# nrf54lv10a_enga_application register map
Vendor: Nordic Semiconductor; Series: nrf54l; File version: 1
CPU: CM33 r0p4, little endian, MPU, FPU, 3 interrupt priority bits, 270 interrupts, 4 SAU regions
Registers are 32-bit, read-write, reset 0x0 unless marked. A register's access mark holds for its fields unless they carry their own. Offsets are from the block's base; [hi:lo] are bit positions; lines under a group give offsets from that group; {n}, {i} and the like mark numbered series; 'fields as' and 'values as' point back to an identical list.

## GLOBAL_KMU_S — Key management unit
Base 0x50049000
0x00 TASKS_PROVISION wo — Provision key slot
  [0] TASKS_PROVISION
    1=Trigger task
0x04 TASKS_PUSH wo — Push key slot
  [0] TASKS_PUSH
    1=Trigger task
0x08 TASKS_REVOKE wo — Revoke key slot
  [0] TASKS_REVOKE
    1=Trigger task
0x0C TASKS_READMETADATA wo — Read key slot metadata into METADATA register
  [0] TASKS_READMETADATA
    1=Trigger task
0x10 TASKS_PUSHBLOCK wo — Block only the PUSH operation of a key slot, preventing the key slot from being PUSHED until next reset. The task is kept for backwards compatibility.
  [0] TASKS_PUSHBLOCK
    1=Trigger task
0x14 TASKS_BLOCK wo — Block the PROVISION, PUSH, and REVOKE operations of a key slot, preventing the key slot from being PROVISIONED, PUSHED, or REVOKED until next reset
  [0] TASKS_BLOCK
    1=Trigger task
0x100 EVENTS_PROVISIONED — Key slot successfully provisioned
  [0] EVENTS_PROVISIONED
    0=NotGenerated (Event not generated); 1=Generated (Event generated)
0x104 EVENTS_PUSHED — Key slot successfully pushed
  [0] EVENTS_PUSHED
    values as EVENTS_PROVISIONED.EVENTS_PROVISIONED
0x108 EVENTS_REVOKED — Key slot has been revoked and can no longer be used
  [0] EVENTS_REVOKED
    values as EVENTS_PROVISIONED.EVENTS_PROVISIONED
0x10C EVENTS_ERROR — Error generated during PROVISION, PUSH, READMETADATA or REVOKE operations. Triggering the PROVISION, PUSH and REVOKE tasks on a BLOCKED keyslot will also generate this event.
  [0] EVENTS_ERROR
    values as EVENTS_PROVISIONED.EVENTS_PROVISIONED
0x110 EVENTS_METADATAREAD — Key slot metadata has been read into METADATA register
  [0] EVENTS_METADATAREAD
    values as EVENTS_PROVISIONED.EVENTS_PROVISIONED
0x114 EVENTS_PUSHBLOCKED — The PUSHBLOCK operation was successful. The event is kept for backwards compatibility.
  [0] EVENTS_PUSHBLOCKED
    values as EVENTS_PROVISIONED.EVENTS_PROVISIONED
0x118 EVENTS_BLOCKED — The BLOCK operation was successful
  [0] EVENTS_BLOCKED
    values as EVENTS_PROVISIONED.EVENTS_PROVISIONED
0x400 STATUS ro — KMU status register
  [0] STATUS — KMU status
    0=Ready (KMU is ready for new operation); 1=Busy (KMU is busy, an operation is in progress)
0x500 KEYSLOT — Select key slot to operate on
  [7:0] ID — Select key slot ID to provision, push, read METADATA, revoke or block when the corresponding task is triggered.
0x504 SRC — Source address for provisioning
  [31:0] SRC — Source address for TASKS_PROVISION.
0x508 METADATA — Key slot metadata as read by TASKS_READMETADATA.
  [31:0] METADATA — Read metadata.

## GLOBAL_ECB00_NS — AES ECB Mode Encryption 0
Base 0x4004B000
Same registers: GLOBAL_ECB00_S 0x5004B000
0x00 TASKS_START wo — Start ECB block encrypt
  [0] TASKS_START
    1=Trigger task
0x04 TASKS_STOP wo — Abort a possible executing ECB operation
  [0] TASKS_STOP
    1=Trigger task
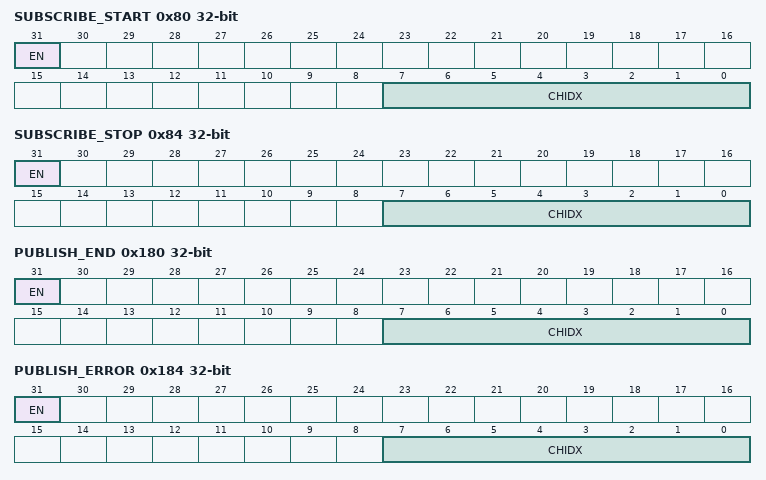
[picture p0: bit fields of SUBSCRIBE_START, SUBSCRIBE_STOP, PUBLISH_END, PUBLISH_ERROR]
0x80 SUBSCRIBE_START — Subscribe configuration for task START
  [31] EN
    0=Disabled (Disable subscription); 1=Enabled (Enable subscription)
  [7:0] CHIDX — DPPI channel that task START will subscribe to
0x84 SUBSCRIBE_STOP — Subscribe configuration for task STOP
  [31] EN
    values as SUBSCRIBE_START.EN
  [7:0] CHIDX — DPPI channel that task STOP will subscribe to
0x100 EVENTS_END — ECB block encrypt complete
  [0] EVENTS_END
    0=NotGenerated (Event not generated); 1=Generated (Event generated)
0x104 EVENTS_ERROR — ECB block encrypt aborted because of a STOP task or due to an error
  [0] EVENTS_ERROR
    values as EVENTS_END.EVENTS_END
0x180 PUBLISH_END — Publish configuration for event END
  [31] EN
    0=Disabled (Disable publishing); 1=Enabled (Enable publishing)
  [7:0] CHIDX — DPPI channel that event END will publish to
0x184 PUBLISH_ERROR — Publish configuration for event ERROR
  [31] EN
    values as PUBLISH_END.EN
  [7:0] CHIDX — DPPI channel that event ERROR will publish to
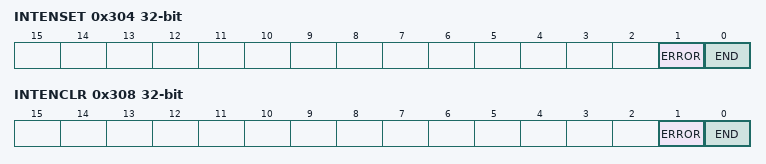
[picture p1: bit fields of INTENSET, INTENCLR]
0x304 INTENSET — Enable interrupt
  [1] ERROR write-1-sets — Write '1' to enable interrupt for event ERROR
    on read: 0=Disabled (Read: Disabled); 1=Enabled (Read: Enabled) | on write: 1=Set (Enable)
  [0] END write-1-sets — Write '1' to enable interrupt for event END
    values as ERROR
0x308 INTENCLR — Disable interrupt
  [1] ERROR write-1-clears — Write '1' to disable interrupt for event ERROR
    on read: 0=Disabled (Read: Disabled); 1=Enabled (Read: Enabled) | on write: 1=Clear (Disable)
  [0] END write-1-clears — Write '1' to disable interrupt for event END
    values as ERROR
0x400 ERRORSTATUS ro
  [2:0] ERRORSTATUS — Error status when the ERROR event is generated
    0=No errors have occurred; 1=PrematureInptrEnd (End of INPTR job list before data structure was read.); 2=PrematureOutptrEnd (End of OUTPTR job list before data structure was read.); 3=EncryptionTooSlow (Deprecated enumerator - Encryption aborted due to higher priority peripheral requesting or using the AES module.); 3=Aborted (Encryption aborted due to higher priority peripheral requesting or using the AES module.); 4=DmaError (Bus error during DMA access.)
0x510 KEY group — Unspecified
  {0x0+4j} VALUE[{j}] (j=0..3) wo — Description collection: 128-bit AES key
    [31:0] VALUE — AES 128-bit key value, bits (32*(n+1))-1 : (32*n)
0x530 IN group — IN EasyDMA channel
  0x00 PTR — Input pointer
    [31:0] PTR — Points to a job list containing unencrypted ECB data structure
0x538 OUT group — OUT EasyDMA channel
  0x00 PTR — Output pointer Points to a job list containing encrypted ECB data structure
    [31:0] PTR — Output pointer
0x53C CSAA group — Channel sounding access address scoring algorithm
  0x00 REFLECTOR ro — Selected Channel Sounding Access Address used in the CS SYNC from Reflector to Initiator
    [31:0] PN
  0x04 INITIATOR ro — Selected Channel Sounding Access Address used in the CS SYNC from Initiator to Reflector
    [31:0] PN
  0x08 MODE — Operation modes
    [0] BITREVERSE — Reverse the endianness on bit level for the ECB output, INITIATOR, and REFLECTOR registers
      0=Default endianness; 1=Reversed endianness

## Notices in the file
Copyright (c) 2010 - 2025, Nordic Semiconductor ASA All rights reserved.
SPDX-License-Identifier: BSD-3-Clause
Redistribution and use in source and binary forms, with or without
modification, are permitted provided that the following conditions are met:
1. Redistributions of source code must retain the above copyright notice, this
list of conditions and the following disclaimer.
2. Redistributions in binary form must reproduce the above copyright
notice, this list of conditions and the following disclaimer in the
documentation and/or other materials provided with the distribution.
3. Neither the name of Nordic Semiconductor ASA nor the names of its
contributors may be used to endorse or promote products derived from this
software without specific prior written permission.
THIS SOFTWARE IS PROVIDED BY THE COPYRIGHT HOLDERS AND CONTRIBUTORS "AS IS"
AND ANY EXPRESS OR IMPLIED WARRANTIES, INCLUDING, BUT NOT LIMITED TO, THE
IMPLIED WARRANTIES OF MERCHANTABILITY, AND FITNESS FOR A PARTICULAR PURPOSE
ARE DISCLAIMED. IN NO EVENT SHALL NORDIC SEMICONDUCTOR ASA OR CONTRIBUTORS BE
LIABLE FOR ANY DIRECT, INDIRECT, INCIDENTAL, SPECIAL, EXEMPLARY, OR
CONSEQUENTIAL DAMAGES (INCLUDING, BUT NOT LIMITED TO, PROCUREMENT OF
SUBSTITUTE GOODS OR SERVICES; LOSS OF USE, DATA, OR PROFITS; OR BUSINESS
INTERRUPTION) HOWEVER CAUSED AND ON ANY THEORY OF LIABILITY, WHETHER IN
CONTRACT, STRICT LIABILITY, OR TORT (INCLUDING NEGLIGENCE OR OTHERWISE)
ARISING IN ANY WAY OUT OF THE USE OF THIS SOFTWARE, EVEN IF ADVISED OF THE
POSSIBILITY OF SUCH DAMAGE.
